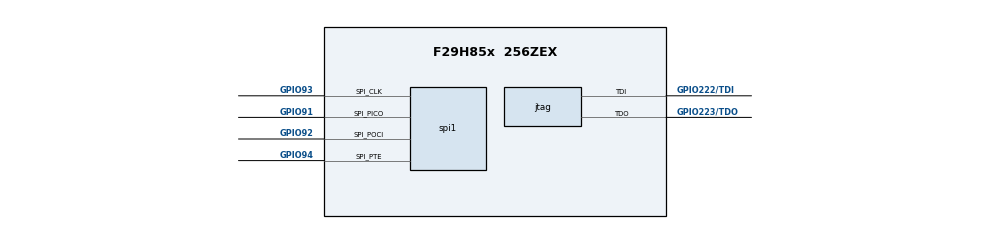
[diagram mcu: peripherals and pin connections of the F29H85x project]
/**
 * @cliArgs --device "F29H85x" --part "F29H85x_256ZEX" --package "256ZEX" --context "CPU3" --product "MCU_SDK_F29H85x@1.00.00.00"
 * @versions {"tool":"1.23.0+4000"}
 */

/**
 * Import the modules used in this configuration.
 */
const jtag = scripting.addModule("/driverlib/jtag.js");
const spi  = scripting.addModule("/driverlib/spi.js", {}, false);
const spi1 = spi.addInstance();

/**
 * Write custom configuration values to the imported modules.
 */
jtag.JTAG.$assign        = "JTAG";
jtag.JTAG.tdoPin.$assign = "GPIO223/TDO";
jtag.JTAG.tdiPin.$assign = "GPIO222/TDI";

spi1.$name                   = "mySPI0";
spi1.useFifo                 = false;
spi1.emulationMode           = "SPI_EMULATION_FREE_RUN";
spi1.useInterrupts           = false;
spi1.spi.$assign             = "SPID";
spi1.spi.spi_picoPin.$assign = "GPIO91";
spi1.spi.spi_pociPin.$assign = "GPIO92";
spi1.spi.spi_clkPin.$assign  = "GPIO93";
spi1.spi.spi_ptePin.$assign  = "GPIO94";
spi1.picoQual.$name          = "myGPIOQUAL0";
spi1.pociQual.$name          = "myGPIOQUAL1";
spi1.clkQual.$name           = "myGPIOQUAL2";
spi1.pteQual.$name           = "myGPIOQUAL3";
spi1.periphClock.$name       = "driverlib_perClock0";
spi1.periphConfig.$name      = "driverlib_perConfig0";
